# STM32F745 register map
File version: 1.6
CPU: CM7 r0p1, little endian, MPU, FPU, 4 interrupt priority bits
Registers are 32-bit, read-write, reset 0x0 unless marked. A register's access mark holds for its fields unless they carry their own. Offsets are from the block's base; [hi:lo] are bit positions; {n}, {i} and the like mark numbered series.

## EXTI — External interrupt/event controller
Base 0x40013C00
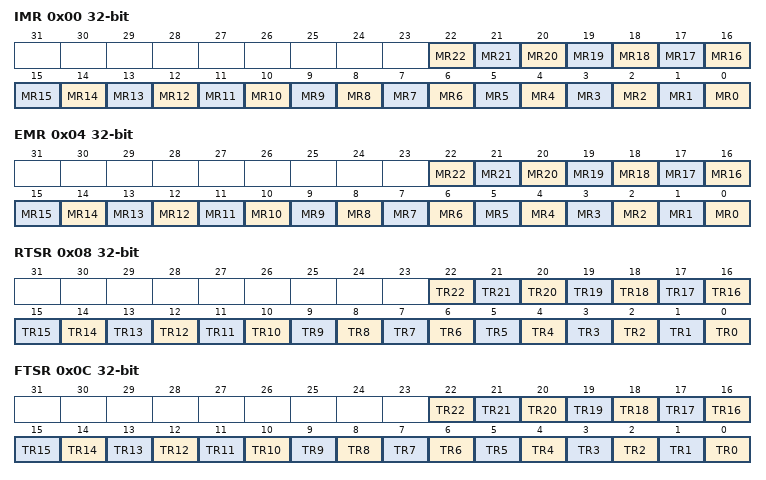
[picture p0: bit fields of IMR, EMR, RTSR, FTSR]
0x00 IMR — Interrupt mask register (EXTI_IMR)
  [n] MR{n} (n=0..22) — Interrupt Mask on line {n}
    0=Masked (Interrupt request line is masked); 1=Unmasked (Interrupt request line is unmasked)
0x04 EMR — Event mask register (EXTI_EMR)
  [n] MR{n} (n=0..22) — Event Mask on line {n}
    0=Masked (Event request line is masked); 1=Unmasked (Event request line is unmasked)
0x08 RTSR — Rising Trigger selection register (EXTI_RTSR)
  [n] TR{n} (n=0..22) — Rising trigger event configuration of line {n}
    0=Disabled (Rising edge trigger is disabled); 1=Enabled (Rising edge trigger is enabled)
0x0C FTSR — Falling Trigger selection register (EXTI_FTSR)
  [n] TR{n} (n=0..22) — Falling trigger event configuration of line {n}
    0=Disabled (Falling edge trigger is disabled); 1=Enabled (Falling edge trigger is enabled)
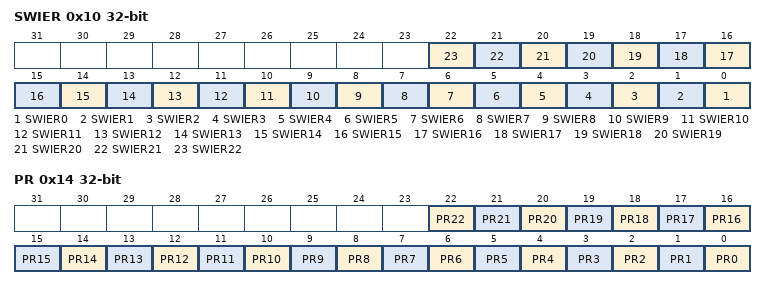
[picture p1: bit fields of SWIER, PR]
0x10 SWIER — Software interrupt event register (EXTI_SWIER)
  [n] SWIER{n} (n=0..22) — Software Interrupt on line {n}
    on write: 1=Pend (Generates an interrupt request)
0x14 PR — Pending register (EXTI_PR)
  [n] PR{n} (n=0..22) write-1-clears — Pending bit {n}
    on read: 0=NotPending (No trigger request occurred); 1=Pending (Selected trigger request occurred) | on write: 1=Clears pending bit

## CEC — HDMI-CEC controller
Base 0x40006C00
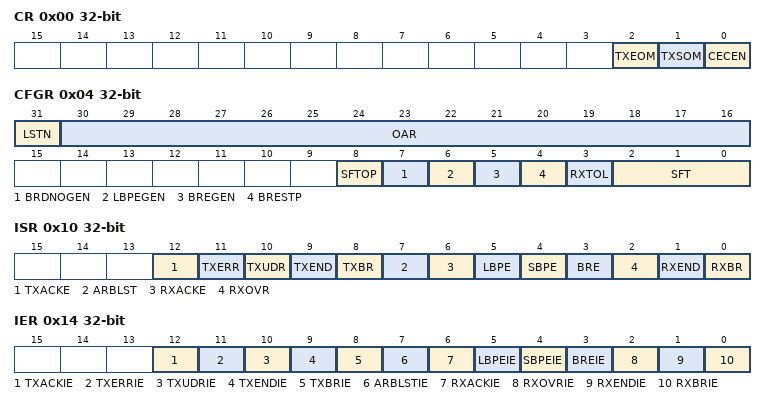
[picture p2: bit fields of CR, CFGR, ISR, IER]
0x00 CR — control register
  [2] TXEOM — Tx End Of Message
  [1] TXSOM — Tx start of message
  [0] CECEN — CEC Enable
0x04 CFGR — configuration register
  [31] LSTN — Listen mode
  [30:16] OAR — Own addresses configuration
  [8] SFTOP — SFT Option Bit
  [7] BRDNOGEN — Avoid Error-Bit Generation in Broadcast
  [6] LBPEGEN — Generate Error-Bit on Long Bit Period Error
  [5] BREGEN — Generate error-bit on bit rising error
  [4] BRESTP — Rx-stop on bit rising error
  [3] RXTOL — Rx-Tolerance
  [2:0] SFT — Signal Free Time
0x08 TXDR wo — Tx data register
  [7:0] TXD — Tx Data register
0x0C RXDR ro — Rx Data Register
  [7:0] RXDR — CEC Rx Data Register
0x10 ISR — Interrupt and Status Register
  [12] TXACKE — Tx-Missing acknowledge error
  [11] TXERR — Tx-Error
  [10] TXUDR — Tx-Buffer Underrun
  [9] TXEND — End of Transmission
  [8] TXBR — Tx-Byte Request
  [7] ARBLST — Arbitration Lost
  [6] RXACKE — Rx-Missing Acknowledge
  [5] LBPE — Rx-Long Bit Period Error
  [4] SBPE — Rx-Short Bit period error
  [3] BRE — Rx-Bit rising error
  [2] RXOVR — Rx-Overrun
  [1] RXEND — End Of Reception
  [0] RXBR — Rx-Byte Received
0x14 IER — interrupt enable register
  [12] TXACKIE — Tx-Missing Acknowledge Error Interrupt Enable
  [11] TXERRIE — Tx-Error Interrupt Enable
  [10] TXUDRIE — Tx-Underrun interrupt enable
  [9] TXENDIE — Tx-End of message interrupt enable
  [8] TXBRIE — Tx-Byte Request Interrupt Enable
  [7] ARBLSTIE — Arbitration Lost Interrupt Enable
  [6] RXACKIE — Rx-Missing Acknowledge Error Interrupt Enable
  [5] LBPEIE — Long Bit Period Error Interrupt Enable
  [4] SBPEIE — Short Bit Period Error Interrupt Enable
  [3] BREIE — Bit Rising Error Interrupt Enable
  [2] RXOVRIE — Rx-Buffer Overrun Interrupt Enable
  [1] RXENDIE — End Of Reception Interrupt Enable
  [0] RXBRIE — Rx-Byte Received Interrupt Enable

## SPDIFRX — Receiver Interface
Base 0x40004000
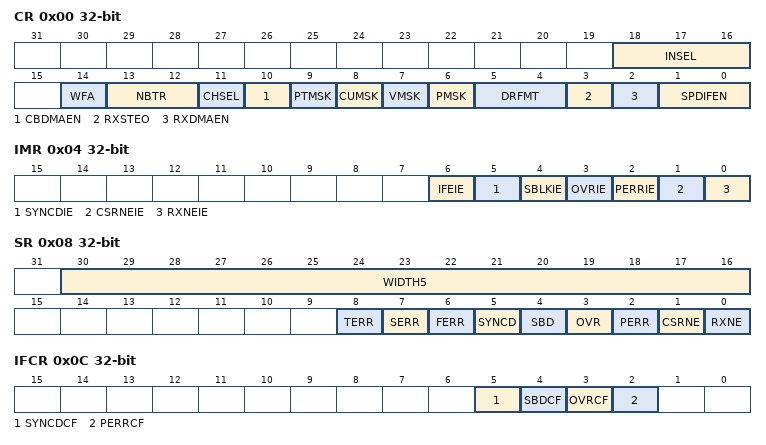
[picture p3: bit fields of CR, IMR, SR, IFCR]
0x00 CR — Control register
  [18:16] INSEL — input selection
  [14] WFA — Wait For Activity
  [13:12] NBTR — Maximum allowed re-tries during synchronization phase
  [11] CHSEL — Channel Selection
  [10] CBDMAEN — Control Buffer DMA ENable for control flow
  [9] PTMSK — Mask of Preamble Type bits
  [8] CUMSK — Mask of channel status and user bits
  [7] VMSK — Mask of Validity bit
  [6] PMSK — Mask Parity error bit
  [5:4] DRFMT — RX Data format
  [3] RXSTEO — STerEO Mode
  [2] RXDMAEN — Receiver DMA ENable for data flow
  [1:0] SPDIFEN — Peripheral Block Enable
0x04 IMR — Interrupt mask register
  [6] IFEIE — Serial Interface Error Interrupt Enable
  [5] SYNCDIE — Synchronization Done
  [4] SBLKIE — Synchronization Block Detected Interrupt Enable
  [3] OVRIE — Overrun error Interrupt Enable
  [2] PERRIE — Parity error interrupt enable
  [1] CSRNEIE — Control Buffer Ready Interrupt Enable
  [0] RXNEIE — RXNE interrupt enable
0x08 SR ro — Status register
  [30:16] WIDTH5 — Duration of 5 symbols counted with SPDIF_CLK
  [8] TERR — Time-out error
  [7] SERR — Synchronization error
  [6] FERR — Framing error
  [5] SYNCD — Synchronization Done
  [4] SBD — Synchronization Block Detected
  [3] OVR — Overrun error
  [2] PERR — Parity error
  [1] CSRNE — Control Buffer register is not empty
  [0] RXNE — Read data register not empty
0x0C IFCR wo — Interrupt Flag Clear register
  [5] SYNCDCF — Clears the Synchronization Done flag
  [4] SBDCF — Clears the Synchronization Block Detected flag
  [3] OVRCF — Clears the Overrun error flag
  [2] PERRCF — Clears the Parity error flag
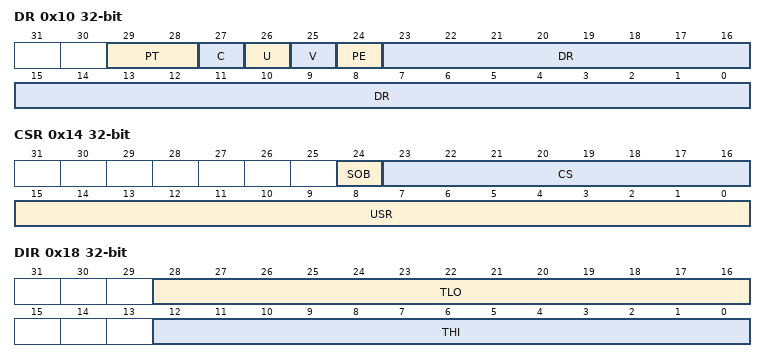
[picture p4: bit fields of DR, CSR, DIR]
0x10 DR ro — Data input register
  [29:28] PT — Preamble Type
  [27] C — Channel Status bit
  [26] U — User bit
  [25] V — Validity bit
  [24] PE — Parity Error bit
  [23:0] DR — Parity Error bit
0x14 CSR ro — Channel Status register
  [24] SOB — Start Of Block
  [23:16] CS — Channel A status information
  [15:0] USR — User data information
0x18 DIR ro — Debug Information register
  [28:16] TLO — Threshold LOW
  [12:0] THI — Threshold HIGH
